VERSION ""

NS_ :

BS_:

BU_: Pegasus Marvel Laptop Stark Xavier stark
VAL_TABLE_ MCU_current_gear 4 "Power" 3 "Eco" 2 "Reverse" 1 "Sports" 0 "Neutral" ;
VAL_TABLE_ Pwm_off_on 1 "On" 0 "Off" ;
VAL_TABLE_ Drive_Mode 1 "Speed" 0 "Torque" ;
VAL_TABLE_ Ready_Status 1 "Ready" 0 "Not Ready" ;
VAL_TABLE_ Fault 1 "Fault" 0 "No fault" ;
VAL_TABLE_ Brake_enable 1 "Drive" 0 "brake" ;
VAL_TABLE_ Motor_direction 1 "Motor fwd" 0 "Motor reverse" ;
VAL_TABLE_ Active_discharge_0n_off 1 "active discharge on" 0 "active discharge off" ;
VAL_TABLE_ Halt_start 1 "Start" 0 "Halt" ;
VAL_TABLE_ Fault_grade 3 "Grade 3 fault" 2 "Grade 2 fault" 1 "Grade 1 fault" 0 "No fault" ;
VAL_TABLE_ MultiMode_Operation 0 "Sports Mode" ;
VAL_TABLE_ Alarm 7 "Speed_limit" 6 "Temp Low" 5 "Under Voltage" 4 "Over Voltage" 3 "Motor Over Heat" 2 "Motor Over Load" 1 "Motor Over Speed" 0 "Encoder_fault" ;
VAL_TABLE_ Vehicle_Status_1 4 "Power on" 3 "Low Voltage Light" 2 "Regnartion_active" 1 "Spr1" 0 "Spr" ;
VAL_TABLE_ Vehicle_status 2 "REV" 1 "FWD" 0 "Park" ;
VAL_TABLE_ MCU_VCU_Fault_Table 1 "fault" 0 "normal" ;
VAL_TABLE_ MCU_VCU_WorkStatus_PWM_Sts 1 "PWM on" 0 "PWM off" ;
VAL_TABLE_ MCU_VCU_WorkStatus_Ctrl_Mode 1 "Speed mode" 0 "Torque mode" ;
VAL_TABLE_ MCU_VCU_WorkStatus_Ready 1 "Ready" 0 "Not Ready" ;
VAL_TABLE_ MCU_VCU_WorkStatus_Fault_Table 1 "fault" 0 "no fault" ;
VAL_TABLE_ MCU_VCU_WorkStatus_Drive_Table 1 "Description for the value '0x1'" 0 "brake" ;
VAL_TABLE_ MCU_VCU_WorkStatus_Direction 1 "motor forward" 0 "motor reverse" ;
VAL_TABLE_ MCU_VCU_WorkStatus_Dischg_Table 1 "active discharge on" 0 "active discharge off" ;
VAL_TABLE_ MCU_VCU_WorkStatus_Halt_Table 1 "start" 0 "halt" ;
VAL_TABLE_ MCU_VCU_Main_Contactor_Table 1 "main contactor on" 0 "main contactor off" ;
VAL_TABLE_ MCU_VCU_Precharge_Table 1 "precharge on" 0 "precharge off" ;
VAL_TABLE_ MCU_VCU_Gear_Table 3 "Brake" 2 "R" 1 "D" 0 "N" ;
VAL_TABLE_ VCU_MCU_HVCircuit_Table 3 "Precharge to main contactor" 2 "main contactor off" 1 "main contactor on" 0 "precharge" ;
VAL_TABLE_ VCU_MCU_Discharge_Table 1 "start" 0 "forbidden" ;
VAL_TABLE_ VCU_MCU_Enable_Table 1 "enable" 0 "disable" ;
VAL_TABLE_ VCU_MCU_Control_Mode_Table 1 "speed" 0 "torque" ;
VAL_TABLE_ VCU_MCU_Valid_Invalid_Table 1 "valid" 0 "invalid" ;

BO_ 3221225472 VECTOR__INDEPENDENT_SIG_MSG: 0 Vector__XXX
 SG_ bms_cycleCount : 0|16@1+ (1,0) [0|65535] "" Vector__XXX
 SG_ bms_mcuCounter : 0|16@1+ (1,0) [0|65535] "" Vector__XXX
 SG_ bms_internalResistance : 0|32@1- (10000,0) [-21474836480000|21474836470000] "" Vector__XXX
 SG_ battery_bms_max_capacity : 0|16@1+ (0.1,0) [0|6553.5] "Ah" Vector__XXX
 SG_ battery_cmu_2_balancing_mask : 0|16@1- (1,0) [0|65535] "" Vector__XXX
 SG_ battery_cmu_1_balancing_mask : 0|16@1- (1,0) [0|65535] "" Vector__XXX
 SG_ battery_bms_errors_since_boot : 0|8@1+ (1,0) [0|255] "" Vector__XXX
 SG_ battery_active_errors_count : 0|16@1+ (1,0) [0|65535] "Value" Vector__XXX
 SG_ battery_state_of_charge : 0|16@1+ (0.01,0) [0|100] "%" Vector__XXX
 SG_ battery_state_of_health : 0|16@1+ (0.01,0) [0|100] "%" Vector__XXX
 SG_ battery_total_voltage : 0|16@1+ (0.1,0) [60|85] "V" Vector__XXX
 SG_ battery_fully_charge_flag : 0|8@1+ (1,0) [0|1] "" Vector__XXX
 SG_ battery_bms_state : 0|8@1+ (1,0) [0|5] "" Vector__XXX
 SG_ battery_precharge_active : 0|8@1+ (1,0) [0|1] "" Vector__XXX
 SG_ battery_balancing_active : 0|8@1+ (1,0) [0|1] "" Vector__XXX
 SG_ battery_current : 0|32@1- (1E-005,0) [-1000|1000] "A" Vector__XXX
 SG_ battery_balancing_limit : 0|16@1+ (0.1,0) [0|4200] "mV" Vector__XXX
 SG_ battery_bms_temperature_1 : 0|8@1+ (1,0) [0|255] "C" Vector__XXX
 SG_ battery_bms_temperature_2 : 0|8@1+ (1,0) [0|255] "C" Vector__XXX
 SG_ battery_bms_temperature_3 : 0|8@1+ (1,0) [0|255] "C" Vector__XXX
 SG_ battery_bms_temperature_4 : 0|8@1+ (1,0) [0|255] "C" Vector__XXX
 SG_ battery_bms_temperature_5 : 0|8@1+ (1,0) [0|255] "C" Vector__XXX
 SG_ battery_bms_temperature_6 : 0|8@1+ (1,0) [0|255] "C" Vector__XXX
 SG_ battery_remaining_battery_capaci : 0|16@1- (0.01,0) [0|3276.7] "Ah" Vector__XXX
 SG_ battery_c_1_v_1 : 0|16@1+ (0.1,0) [3100|4200] "mV" Vector__XXX
 SG_ battery_c_1_v_2 : 0|16@1+ (0.1,0) [3100|4200] "mV" Vector__XXX
 SG_ battery_c_1_v_3 : 0|16@1+ (0.1,0) [3100|4200] "mV" Vector__XXX
 SG_ battery_c_1_v_4 : 0|16@1+ (0.1,0) [3100|4200] "mV" Vector__XXX
 SG_ battery_c_1_v_5 : 0|16@1+ (0.1,0) [3100|4200] "mV" Vector__XXX
 SG_ battery_c_1_v_6 : 0|16@1+ (0.1,0) [3100|4200] "mV" Vector__XXX
 SG_ battery_c_1_v_7 : 0|16@1+ (0.1,0) [3100|4200] "mV" Vector__XXX
 SG_ battery_c_1_v_8 : 0|16@1+ (0.1,0) [3100|4200] "mV" Vector__XXX
 SG_ battery_c_1_v_9 : 0|16@1+ (0.1,0) [3100|4200] "mV" Vector__XXX
 SG_ battery_c_1_v_10 : 0|16@1+ (0.1,0) [3100|4200] "mV" Vector__XXX
 SG_ battery_c_1_v_11 : 0|16@1+ (0.1,0) [3100|4200] "mV" Vector__XXX
 SG_ battery_c_1_v_12 : 0|16@1+ (0.1,0) [3100|4200] "mV" Vector__XXX
 SG_ battery_c_2_v_1 : 0|16@1+ (0.1,0) [3100|4200] "mV" Vector__XXX
 SG_ battery_c_2_v_2 : 0|16@1+ (0.1,0) [3100|4200] "mV" Vector__XXX
 SG_ battery_c_2_v_3 : 0|16@1+ (0.1,0) [3100|4200] "mV" Vector__XXX
 SG_ battery_c_2_v_4 : 0|16@1+ (0.1,0) [3100|4200] "mV" Vector__XXX
 SG_ battery_c_2_v_9 : 0|16@1+ (0.1,0) [3100|4200] "mV" Vector__XXX
 SG_ battery_c_2_v_10 : 0|16@1+ (0.1,0) [3100|4200] "mV" Vector__XXX
 SG_ battery_c_2_v_11 : 0|16@1+ (0.1,0) [3100|4200] "mV" Vector__XXX
 SG_ battery_c_2_v_12 : 0|16@1+ (0.1,0) [3100|4200] "mV" Vector__XXX
 SG_ battery_c_2_v_5 : 0|16@1+ (0.1,0) [3100|4200] "mV" Vector__XXX
 SG_ battery_c_2_v_6 : 0|16@1+ (0.1,0) [3100|4200] "mV" Vector__XXX
 SG_ battery_c_2_v_7 : 0|16@1+ (0.1,0) [3100|4200] "mV" Vector__XXX
 SG_ battery_c_2_v_8 : 0|16@1+ (0.1,0) [3100|4200] "mV" Vector__XXX
 SG_ battery_bms_dynamic_in_limit : 0|16@1- (0.1,0) [-3276.8|3276.7] "A" Vector__XXX
 SG_ battery_bms_dynamic_out_limit : 0|16@1- (0.1,0) [-3276.8|3276.7] "A" Vector__XXX
 SG_ battery_bms_config_id : 0|8@1- (1,0) [-128|127] "" Vector__XXX
 SG_ battery_bms_version : 0|16@1+ (1,0) [0|4294967295] "" Vector__XXX
 SG_ battery_bms_requested_current : 0|16@0+ (0.1,0) [0|6553.5] "" Vector__XXX
 SG_ battery_bms_requested_voltage : 0|16@0+ (0.1,0) [0|6553.5] "" Vector__XXX
 SG_ controller_os_version : 0|8@1+ (1,0) [0|255] "" Vector__XXX
 SG_ controller_vcl_build_number : 0|8@1+ (1,0) [0|255] "" Vector__XXX
 SG_ controller_vcl_version : 0|8@1+ (1,0) [0|255] "" Vector__XXX
 SG_ controller_serial_number : 0|24@1+ (1,0) [0|255] "" Vector__XXX
 SG_ controller_config_version : 0|8@1+ (1,0) [0|0] "" Vector__XXX
 SG_ controller_os_build_number : 0|8@1+ (1,0) [0|0] "" Vector__XXX
 SG_ Baud_Rate_Change : 0|8@1+ (1,0) [0|2] "" Vector__XXX
 SG_ Regen_Off : 0|8@1+ (1,0) [0|255] "" Vector__XXX
 SG_ Brake_Current_Limit : 0|8@1+ (1,0) [5|100] "Percent" Vector__XXX
 SG_ Regen_Current_Limit : 0|8@1+ (1,0) [5|100] "Percent" Vector__XXX
 SG_ Drive_Current_Limit : 0|8@1+ (1,0) [10|100] "Percent" Vector__XXX
 SG_ Brake_Rate : 0|8@1+ (0.1,0) [1|250] "Sec" Vector__XXX
 SG_ Accel_Release_Rate : 0|8@1- (0.1,0) [1|250] "Sec" Vector__XXX
 SG_ Accel_Rate : 0|8@1+ (0.1,0) [1|250] "Sec" Vector__XXX
 SG_ Invalid_BMS_Data : 0|8@1+ (1,0) [0|255] "" Vector__XXX
 SG_ controller_vehicle_power_mode : 0|8@1+ (1,0) [0|255] "" Vector__XXX
 SG_ controller_battery_energy_consum : 0|8@1+ (0.1,0) [0|25.5] "KWhr" Vector__XXX
 SG_ controller_battery_power_consume : 0|8@1+ (0.1,0) [0|25.5] "KW" Vector__XXX
 SG_ controller_motor_torque_estimate : 0|16@1- (0.1,0) [-100|100] "Nm" Vector__XXX
 SG_ controller_main_state : 0|8@1+ (1,0) [0|0] "" Vector__XXX
 SG_ controller_frequency : 0|16@1- (1,0) [-500|500] "Hz" Vector__XXX
 SG_ controller_current_rms : 0|16@1+ (1,0) [0|255] "%" Vector__XXX
 SG_ controller_voltage_rms : 0|8@1+ (1,0) [0|255] "Amp" Vector__XXX
 SG_ controller_master_timer : 0|32@1- (1,0) [-2147483648|2147483647] "" Vector__XXX
 SG_ controller_motor_rpm : 0|16@1+ (1,0) [0|65535] "RPM" Vector__XXX
 SG_ controller_battery_keyswitch_vol : 0|8@1+ (1,0) [0|255] "Volt" Vector__XXX
 SG_ controller_battery_capacity_volt : 0|8@1+ (1,0) [0|255] "Volt" Vector__XXX
 SG_ controller_potential_to_row : 0|8@1+ (0.1,0) [0|25.5] "V" Vector__XXX
 SG_ controller_brake_mapped : 0|8@1+ (1,0) [0|255] "%" Vector__XXX
 SG_ controller_brake_command : 0|8@1+ (1,0) [0|255] "%" Vector__XXX
 SG_ controller_throttle_potentiomete : 0|8@1+ (0.1,0) [0|25.5] "V" Vector__XXX
 SG_ controller_throttle_mapped : 0|8@1+ (1,0) [0|255] "%" Vector__XXX
 SG_ controller_throttle_multiplier : 0|8@1+ (1,0) [0|255] "%" Vector__XXX
 SG_ controller_throttle_command : 0|8@1+ (1,0) [0|255] "%" Vector__XXX
 SG_ controller_fault_flag_0 : 0|8@1+ (1,0) [0|255] "" Vector__XXX
 SG_ controller_fault_flag_1 : 0|8@1+ (1,0) [0|255] "" Vector__XXX
 SG_ controller_fault_flag_2 : 0|8@1+ (1,0) [0|255] "" Vector__XXX
 SG_ controller_fault_flag_3 : 0|8@1+ (1,0) [0|255] "" Vector__XXX
 SG_ controller_fault_flag_4 : 0|8@1+ (1,0) [0|255] "" Vector__XXX
 SG_ controller_fault_flag_5 : 0|8@1+ (1,0) [0|255] "" Vector__XXX
 SG_ controller_fault_flag_6 : 0|8@1+ (1,0) [0|255] "" Vector__XXX
 SG_ controller_fault_flag_7 : 0|8@1+ (1,0) [0|255] "" Vector__XXX
 SG_ controller_trip_low_high : 0|16@1+ (1,0) [0|255] "%" Vector__XXX
 SG_ controller_alarm_fault : 0|8@1+ (1,0) [0|255] "" Vector__XXX
 SG_ controller_assist_level_gear : 0|8@1+ (1,0) [0|255] "" Vector__XXX
 SG_ controller_vehicle_status : 0|8@1+ (1,0) [0|0] "" Vector__XXX
 SG_ controller_odometer : 0|32@1+ (0.1,0) [0|429496729.5] "KM" Vector__XXX
 SG_ controller_battery_discharge_rat : 0|8@1- (1,0) [-128|127] "" Vector__XXX
 SG_ controller_soc : 0|8@1- (1,0) [-128|127] "" Vector__XXX
 SG_ controller_temperature : 0|8@1+ (1,-50) [-50|200] "degree_C" Vector__XXX
 SG_ controller_motor_temperature : 0|8@1+ (1,-50) [-50|200] "Degree_C" Vector__XXX
 SG_ VCU_Canlife : 0|4@1+ (1,0) [0|0] "" Vector__XXX
 SG_ VCU_HVCircuit : 0|2@1+ (1,0) [0|0] "" Vector__XXX
 SG_ VCU_Discharge : 0|1@1+ (1,0) [0|0] "" Vector__XXX
 SG_ VCU_Enable : 0|1@1+ (1,0) [0|0] "" Vector__XXX
 SG_ VCU_ModeReq_control_mode : 0|1@1+ (1,0) [0|0] "" Vector__XXX
 SG_ VCU_ModeReq_reverse : 0|1@1+ (1,0) [0|0] "" Vector__XXX
 SG_ VCU_ModeReq_brake : 0|1@1+ (1,0) [0|0] "" Vector__XXX
 SG_ VCU_ModeReq_forward : 0|1@1+ (1,0) [0|0] "" Vector__XXX
 SG_ VCU_ModeReq_idle : 0|1@1+ (1,0) [0|0] "" Vector__XXX
 SG_ VCU_ModeReq_halt : 0|1@1+ (1,0) [0|0] "" Vector__XXX
 SG_ VCU_SpdReq : 0|16@1+ (1,-32000) [0|0] "rpm" Vector__XXX
 SG_ VCU_TrqReq : 0|16@1+ (0.1,-3200) [0|0] "Nm" Vector__XXX

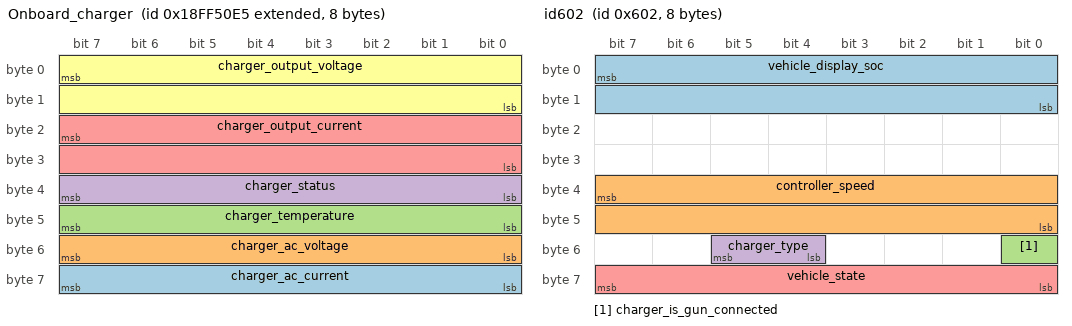
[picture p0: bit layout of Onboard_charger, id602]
BO_ 2566869221 Onboard_charger: 8 Vector__XXX
 SG_ charger_ac_current : 63|8@0+ (0.1,0) [0|255] "" Vector__XXX
 SG_ charger_ac_voltage : 55|8@0+ (1,0) [0|255] "" Vector__XXX
 SG_ charger_temperature : 47|8@0+ (1,0) [0|255] "" Vector__XXX
 SG_ charger_status : 39|8@0+ (1,0) [0|255] "" Vector__XXX
 SG_ charger_output_current : 23|16@0+ (0.1,0) [0|255] "" Vector__XXX
 SG_ charger_output_voltage : 7|16@0+ (0.1,0) [0|255] "" Vector__XXX

BO_ 2550588916 Stark_charger: 8 Vector__XXX
 SG_ charger_requested_current : 23|16@0+ (0.1,0) [0|255] "" Vector__XXX
 SG_ charger_requested_voltage : 7|16@0+ (0.1,0) [0|255] "" Vector__XXX

BO_ 1538 id602: 8 stark
 SG_ vehicle_display_soc : 7|16@0+ (0.1,0) [0|0] "" Vector__XXX
 SG_ controller_speed : 39|16@0+ (0.1,0) [0|65535] "" Vector__XXX
 SG_ charger_is_gun_connected : 48|1@1+ (1,0) [0|2] "" Vector__XXX
 SG_ charger_type : 52|2@1+ (1,0) [0|3] "" Vector__XXX
 SG_ vehicle_state : 63|8@0+ (1,0) [0|10] "" Vector__XXX

BO_ 1539 id603: 8 stark
 SG_ vehicle_calculated_odo : 23|32@0+ (0.01,0) [0|429496729.5] "Km" Vector__XXX

BO_ 1542 id606: 8 Vector__XXX
 SG_ vehicle_aux_charing_flag : 7|8@0+ (1,0) [0|3] "" Vector__XXX
 SG_ vehicle_aux_battery_voltage : 15|16@0+ (0.01,0) [0|655.35] "" Vector__XXX

BO_ 1541 id605: 8 Vector__XXX
 SG_ vehicle_stark_ticks : 7|32@0+ (1,0) [0|4294967295] "" Vector__XXX
 SG_ telemetry_start_index : 39|32@0+ (1,0) [0|4294967295] "" Vector__XXX

BO_ 1545 id609: 8 Vector__XXX
 SG_ vehicle_igni_debounce_count : 39|32@0+ (1,0) [0|4294967295] "" Vector__XXX
 SG_ vehicle_igni_cycle_count : 7|32@0+ (1,0) [0|4294967295] "" Vector__XXX

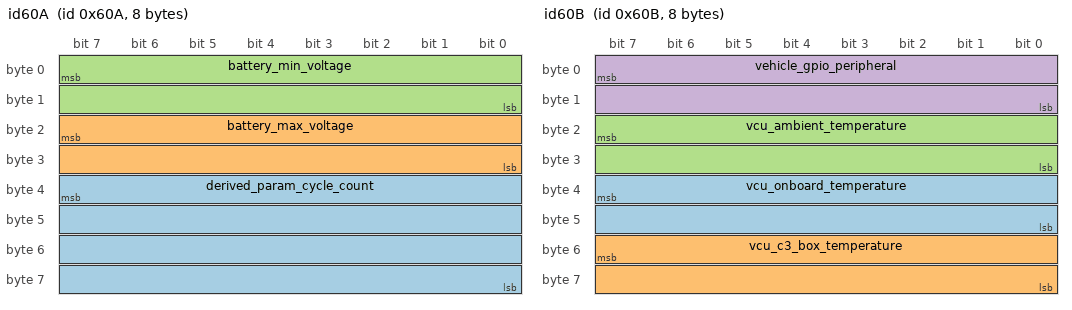
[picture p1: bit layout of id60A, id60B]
BO_ 1546 id60A: 8 Vector__XXX
 SG_ derived_param_cycle_count : 39|32@0+ (1,0) [0|4294967295] "" Vector__XXX
 SG_ battery_max_voltage : 23|16@0+ (0.1,0) [0|6553.5] "" Vector__XXX
 SG_ battery_min_voltage : 7|16@0+ (0.1,0) [0|6553.5] "" Vector__XXX

BO_ 1547 id60B: 8 Vector__XXX
 SG_ vcu_onboard_temperature : 39|16@0+ (0.1,0) [0|6553.5] "C" Vector__XXX
 SG_ vcu_c3_box_temperature : 55|16@0+ (0.1,0) [0|6553.5] "C" Vector__XXX
 SG_ vcu_ambient_temperature : 23|16@0+ (0.1,0) [0|6553.5] "C" Vector__XXX
 SG_ vehicle_gpio_peripheral : 7|16@0+ (1,0) [0|65535] "" Vector__XXX

BO_ 1548 id60C: 8 Vector__XXX
 SG_ vcu_uid1 : 7|64@0+ (1,0) [0|1.8446744074E+019] "" Vector__XXX

BO_ 1549 id60D: 8 Vector__XXX
 SG_ vcu_uid2 : 7|32@0+ (1,0) [0|4294967295] "" Vector__XXX

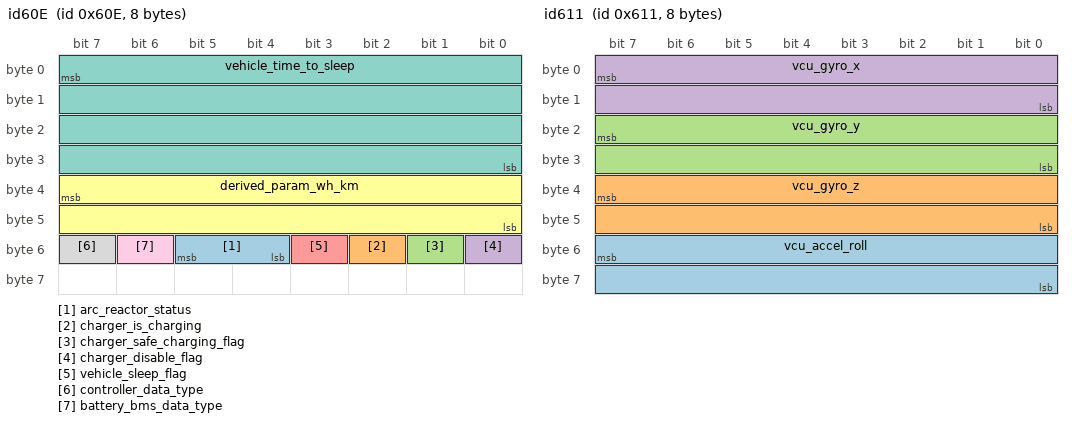
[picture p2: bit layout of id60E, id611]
BO_ 1550 id60E: 8 Vector__XXX
 SG_ arc_reactor_status : 52|2@1+ (1,0) [0|3] "" Vector__XXX
 SG_ charger_is_charging : 50|1@1+ (1,0) [0|1] "" Vector__XXX
 SG_ charger_safe_charging_flag : 49|1@1+ (1,0) [0|1] "" Vector__XXX
 SG_ charger_disable_flag : 48|1@1+ (1,0) [0|1] "" Vector__XXX
 SG_ vehicle_sleep_flag : 51|1@1+ (1,0) [0|1] "" Vector__XXX
 SG_ derived_param_wh_km : 39|16@0+ (0.1,0) [0|6553.5] "" Vector__XXX
 SG_ vehicle_time_to_sleep : 7|32@0+ (1,0) [0|4294967295] "" Vector__XXX
 SG_ controller_data_type : 55|1@1+ (1,0) [0|0] "" Vector__XXX
 SG_ battery_bms_data_type : 54|1@1+ (1,0) [0|0] "" Vector__XXX

BO_ 1552 id610: 8 Vector__XXX
 SG_ vehicle_ecu_manifest_crc : 39|32@0+ (1,0) [0|4294967295] "" Vector__XXX
 SG_ vehicle_manifest_crc : 7|32@0+ (1,0) [0|4294967295] "" Vector__XXX

BO_ 1553 id611: 8 Vector__XXX
 SG_ vcu_accel_roll : 55|16@0- (0.01,0) [-32768|32767] "" Vector__XXX
 SG_ vcu_gyro_z : 39|16@0- (0.01,0) [-32768|32767] "" Vector__XXX
 SG_ vcu_gyro_y : 23|16@0- (0.01,0) [-32768|32767] "" Vector__XXX
 SG_ vcu_gyro_x : 7|16@0- (0.01,0) [-327.68|327.67] "" Vector__XXX

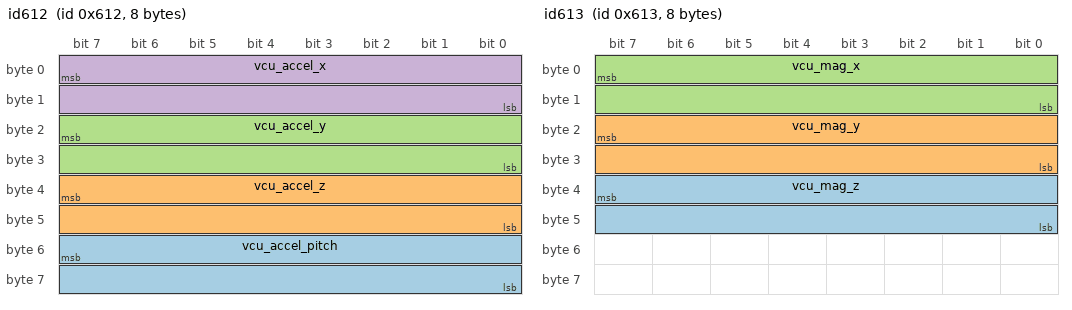
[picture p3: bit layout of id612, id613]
BO_ 1554 id612: 8 Vector__XXX
 SG_ vcu_accel_pitch : 55|16@0- (0.01,0) [-32768|32767] "" Vector__XXX
 SG_ vcu_accel_z : 39|16@0- (0.01,0) [-32768|32767] "" Vector__XXX
 SG_ vcu_accel_y : 23|16@0- (0.01,0) [-32768|32767] "" Vector__XXX
 SG_ vcu_accel_x : 7|16@0- (0.01,0) [-327.68|327.67] "" Vector__XXX

BO_ 1555 id613: 8 Vector__XXX
 SG_ vcu_mag_z : 39|16@0- (0.1,0) [-32768|32767] "" Vector__XXX
 SG_ vcu_mag_y : 23|16@0- (0.1,0) [-32768|32767] "" Vector__XXX
 SG_ vcu_mag_x : 7|16@0- (0.1,0) [-327.68|327.67] "" Vector__XXX

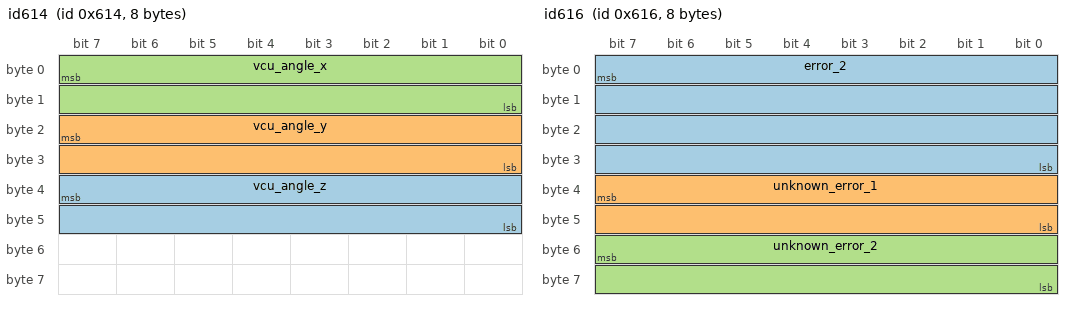
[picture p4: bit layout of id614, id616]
BO_ 1556 id614: 8 Vector__XXX
 SG_ vcu_angle_z : 39|16@0- (0.1,0) [-32768|32767] "" Vector__XXX
 SG_ vcu_angle_y : 23|16@0- (0.1,0) [-32768|32767] "" Vector__XXX
 SG_ vcu_angle_x : 7|16@0- (0.1,0) [-327.68|327.67] "" Vector__XXX

BO_ 1557 id615: 8 Vector__XXX
 SG_ error_1 : 7|64@0+ (1,0) [-32768|32767] "" Vector__XXX

BO_ 1558 id616: 8 Vector__XXX
 SG_ error_2 : 7|32@0+ (1,0) [-32768|32767] "" Vector__XXX
 SG_ unknown_error_1 : 39|16@0+ (1,0) [-32768|32767] "" Vector__XXX
 SG_ unknown_error_2 : 55|16@0+ (1,0) [-327.68|327.67] "" Vector__XXX

BO_ 1559 id617: 8 Vector__XXX
 SG_ controller_error : 7|32@0+ (1,0) [0|0] "" Vector__XXX

BO_ 1026 display_3: 8 Stark
 SG_ vehicle_calculated_trip : 32|32@1+ (0.1,0) [0|0] ""  Xavier

BO_ 1025 display_2: 8 Stark
 SG_ vehicle_ttfc : 32|16@1+ (1,0) [0|0] ""  Xavier
 SG_ vehicle_range : 16|16@1+ (0.1,0) [0|0] ""  Xavier

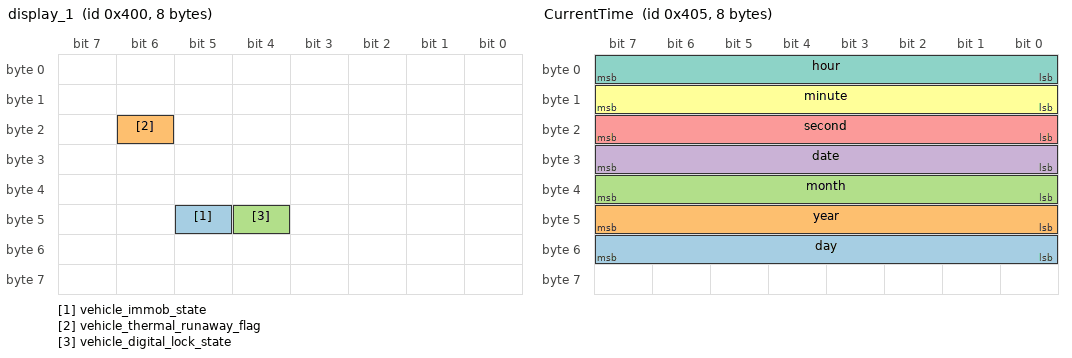
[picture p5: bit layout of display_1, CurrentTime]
BO_ 1024 display_1: 8 Stark
 SG_ vehicle_immob_state : 45|1@1+ (1,0) [0|1] "" Vector__XXX
 SG_ vehicle_thermal_runaway_flag : 22|1@1+ (1,0) [0|1] "" Vector__XXX
 SG_ vehicle_digital_lock_state : 44|1@1+ (1,0) [0|1] "" Vector__XXX

BO_ 1969 GetGITSHA: 8 Xavier
 SG_ git_shaw : 16|32@1+ (1,0) [0|4294967295] ""  Laptop
 SG_ device_id : 0|8@1+ (1,0) [0|255] ""  Laptop

BO_ 1029 CurrentTime: 8 Xavier
 SG_ day : 48|8@1+ (1,0) [0|255] ""  Laptop,Stark
 SG_ year : 40|8@1+ (1,0) [0|255] ""  Laptop,Stark
 SG_ month : 32|8@1+ (1,0) [0|255] ""  Laptop,Stark
 SG_ date : 24|8@1+ (1,0) [0|255] ""  Laptop,Stark
 SG_ second : 16|8@1+ (1,0) [0|255] ""  Laptop,Stark
 SG_ minute : 8|8@1+ (1,0) [0|255] ""  Laptop,Stark
 SG_ hour : 0|8@1+ (1,0) [0|255] ""  Laptop,Stark

BO_ 1783 sim_number_16_20: 8 Xavier
 SG_ sim_16_20 : 0|32@1+ (1,0) [0|4294967295] ""  Laptop

BO_ 1782 sim_number_0_16: 8 Xavier
 SG_ sim_0_16 : 0|64@1+ (1,0) [0|9.2233720369E+018] ""  Laptop

BO_ 1779 xavier_1: 8 Xavier
 SG_ imei : 0|64@1+ (1,0) [0|9.2233720369E+018] ""  Laptop

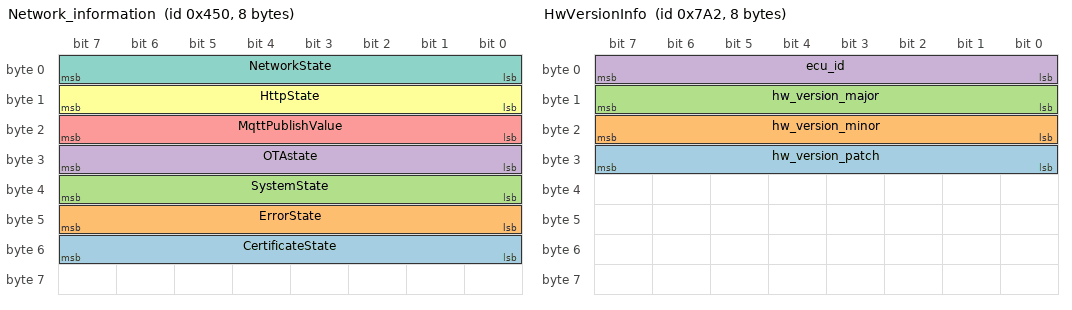
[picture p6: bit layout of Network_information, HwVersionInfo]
BO_ 1104 Network_information: 8 Xavier
 SG_ CertificateState : 48|8@1+ (1,0) [0|255] ""  Laptop
 SG_ ErrorState : 40|8@1+ (1,0) [0|255] ""  Laptop
 SG_ SystemState : 32|8@1+ (1,0) [0|255] ""  Laptop
 SG_ OTAstate : 24|8@1+ (1,0) [0|255] ""  Laptop
 SG_ MqttPublishValue : 16|8@1+ (1,0) [0|255] ""  Laptop
 SG_ HttpState : 8|8@1+ (1,0) [0|255] ""  Laptop
 SG_ NetworkState : 0|8@1+ (1,0) [0|0] ""  Laptop

BO_ 1954 HwVersionInfo: 8 Xavier
 SG_ hw_version_patch : 24|8@1+ (1,0) [0|255] ""  Laptop,Stark
 SG_ hw_version_minor : 16|8@1+ (1,0) [0|255] ""  Laptop,Stark
 SG_ hw_version_major : 8|8@1+ (1,0) [0|255] ""  Laptop,Stark
 SG_ ecu_id : 0|8@1+ (1,0) [0|255] ""  Stark,Laptop

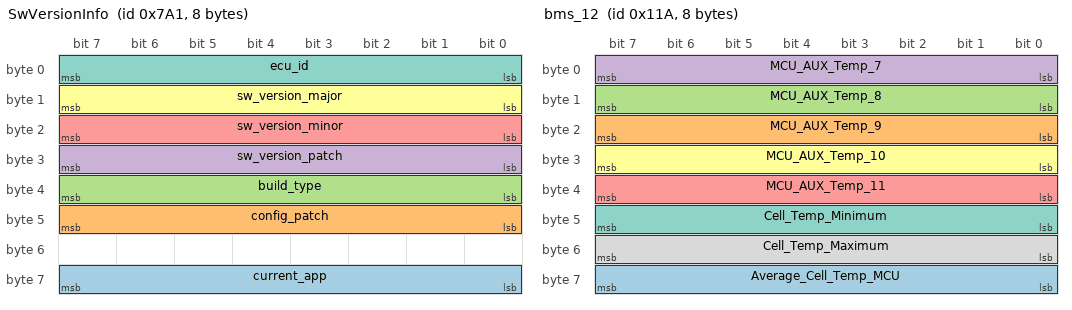
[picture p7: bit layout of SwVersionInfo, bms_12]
BO_ 1953 SwVersionInfo: 8 Xavier
 SG_ current_app : 56|8@1+ (1,0) [0|255] ""  Laptop,Stark
 SG_ config_patch : 40|8@1+ (1,0) [0|255] ""  Laptop,Stark
 SG_ build_type : 32|8@1+ (1,0) [0|255] ""  Laptop,Stark
 SG_ sw_version_patch : 24|8@1+ (1,0) [0|255] ""  Laptop,Stark
 SG_ sw_version_minor : 16|8@1+ (1,0) [0|255] ""  Laptop,Stark
 SG_ sw_version_major : 8|8@1+ (1,0) [0|255] ""  Laptop,Stark
 SG_ ecu_id : 0|8@1+ (1,0) [0|255] ""  Laptop,Stark

BO_ 282 bms_12: 8 Vector__XXX
 SG_ Average_Cell_Temp_MCU : 56|8@1+ (1,0) [0|255] "C" Vector__XXX
 SG_ MCU_AUX_Temp_9 : 16|8@1+ (1,0) [0|255] "C" Vector__XXX
 SG_ MCU_AUX_Temp_8 : 8|8@1+ (1,0) [0|255] "C" Vector__XXX
 SG_ MCU_AUX_Temp_7 : 0|8@1+ (1,0) [0|255] "C" Vector__XXX
 SG_ MCU_AUX_Temp_11 : 32|8@1+ (1,0) [0|255] "C" Vector__XXX
 SG_ MCU_AUX_Temp_10 : 24|8@1+ (1,0) [0|255] "C" Vector__XXX
 SG_ Cell_Temp_Minimum : 40|8@1+ (1,0) [0|255] "C" Vector__XXX
 SG_ Cell_Temp_Maximum : 48|8@1+ (1,0) [0|255] "C" Vector__XXX

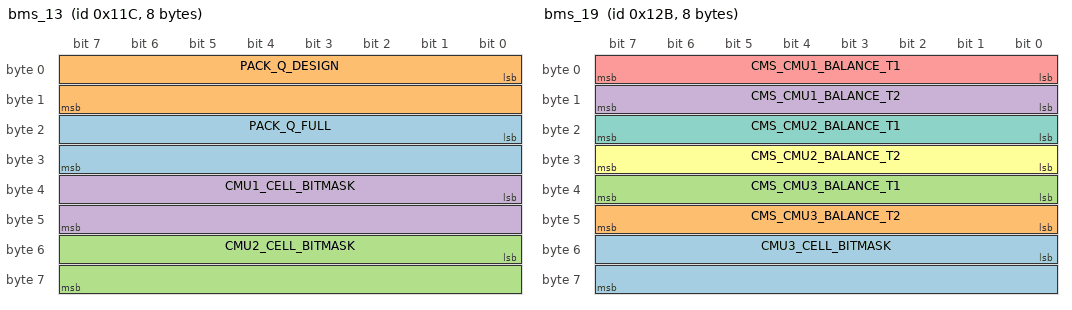
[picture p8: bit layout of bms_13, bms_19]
BO_ 284 bms_13: 8 Vector__XXX
 SG_ PACK_Q_FULL : 16|16@1+ (0.1,0) [0|6553.5] "Ah" Vector__XXX
 SG_ PACK_Q_DESIGN : 0|16@1+ (0.1,0) [0|6553.5] "Ah" Vector__XXX
 SG_ CMU2_CELL_BITMASK : 48|16@1+ (1,0) [0|65535] "" Vector__XXX
 SG_ CMU1_CELL_BITMASK : 32|16@1+ (1,0) [0|65535] "" Vector__XXX

BO_ 299 bms_19: 8 Vector__XXX
 SG_ CMU3_CELL_BITMASK : 48|16@1+ (1,0) [0|65535] "" Vector__XXX
 SG_ CMS_CMU3_BALANCE_T2 : 40|8@1+ (1,0) [0|255] "C" Vector__XXX
 SG_ CMS_CMU3_BALANCE_T1 : 32|8@1+ (1,0) [0|255] "C" Vector__XXX
 SG_ CMS_CMU1_BALANCE_T2 : 8|8@1+ (1,0) [0|255] "C" Vector__XXX
 SG_ CMS_CMU1_BALANCE_T1 : 0|8@1+ (1,0) [0|255] "C" Vector__XXX
 SG_ CMS_CMU2_BALANCE_T2 : 24|8@1+ (1,0) [0|255] "C" Vector__XXX
 SG_ CMS_CMU2_BALANCE_T1 : 16|8@1+ (1,0) [0|255] "C" Vector__XXX

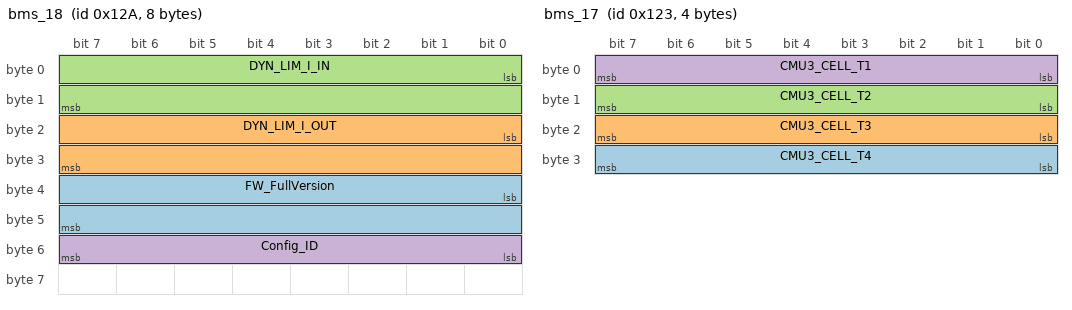
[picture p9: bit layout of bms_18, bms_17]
BO_ 298 bms_18: 8 Vector__XXX
 SG_ FW_FullVersion : 32|16@1+ (1,0) [0|65535] "" Vector__XXX
 SG_ DYN_LIM_I_OUT : 16|16@1+ (0.1,0) [0|6553.5] "A" Vector__XXX
 SG_ DYN_LIM_I_IN : 0|16@1+ (0.1,0) [0|6553.5] "A" Vector__XXX
 SG_ Config_ID : 48|8@1+ (1,0) [0|255] "" Vector__XXX

BO_ 291 bms_17: 4 Vector__XXX
 SG_ CMU3_CELL_T4 : 24|8@1+ (1,0) [0|255] "C" Vector__XXX
 SG_ CMU3_CELL_T3 : 16|8@1+ (1,0) [0|255] "C" Vector__XXX
 SG_ CMU3_CELL_T2 : 8|8@1+ (1,0) [0|255] "C" Vector__XXX
 SG_ CMU3_CELL_T1 : 0|8@1+ (1,0) [0|255] "C" Vector__XXX

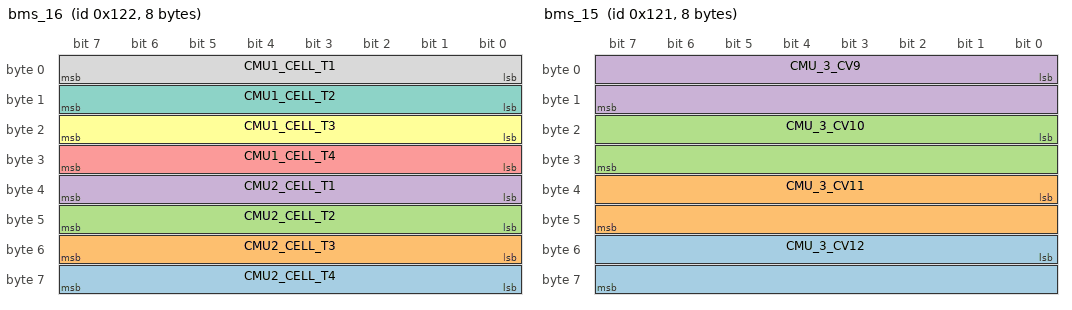
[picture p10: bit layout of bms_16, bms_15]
BO_ 290 bms_16: 8 Vector__XXX
 SG_ CMU2_CELL_T4 : 56|8@1+ (1,0) [0|255] "C" Vector__XXX
 SG_ CMU2_CELL_T3 : 48|8@1+ (1,0) [0|255] "C" Vector__XXX
 SG_ CMU2_CELL_T2 : 40|8@1+ (1,0) [0|255] "C" Vector__XXX
 SG_ CMU2_CELL_T1 : 32|8@1+ (1,0) [0|255] "C" Vector__XXX
 SG_ CMU1_CELL_T4 : 24|8@1+ (1,0) [0|255] "C" Vector__XXX
 SG_ CMU1_CELL_T3 : 16|8@1+ (1,0) [0|255] "C" Vector__XXX
 SG_ CMU1_CELL_T2 : 8|8@1+ (1,0) [0|255] "C" Vector__XXX
 SG_ CMU1_CELL_T1 : 0|8@1+ (1,0) [0|255] "C" Vector__XXX

BO_ 289 bms_15: 8 Vector__XXX
 SG_ CMU_3_CV12 : 48|16@1+ (0.1,0) [0|6553.5] "mV" Vector__XXX
 SG_ CMU_3_CV11 : 32|16@1+ (0.1,0) [0|6553.5] "mV" Vector__XXX
 SG_ CMU_3_CV10 : 16|16@1+ (0.1,0) [0|6553.5] "mV" Vector__XXX
 SG_ CMU_3_CV9 : 0|16@1+ (0.1,0) [0|6553.5] "mV" Vector__XXX

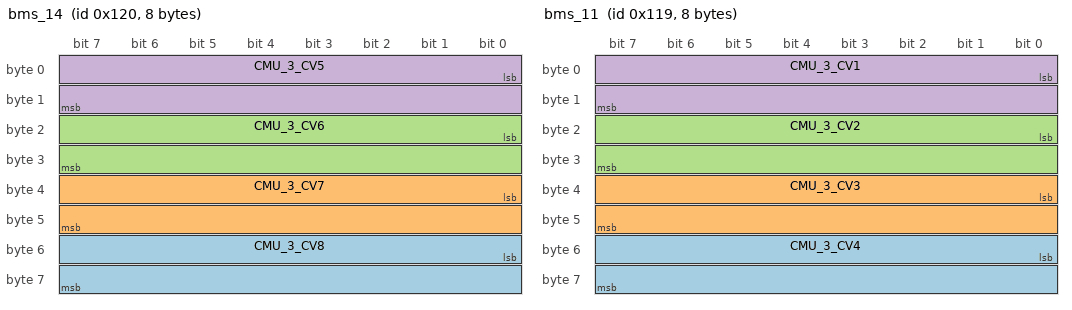
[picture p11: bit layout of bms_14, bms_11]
BO_ 288 bms_14: 8 Vector__XXX
 SG_ CMU_3_CV8 : 48|16@1+ (0.1,0) [0|6553.5] "mV" Vector__XXX
 SG_ CMU_3_CV7 : 32|16@1+ (0.1,0) [0|6553.5] "mV" Vector__XXX
 SG_ CMU_3_CV6 : 16|16@1+ (0.1,0) [0|6553.5] "mV" Vector__XXX
 SG_ CMU_3_CV5 : 0|16@1+ (0.1,0) [0|6553.5] "mV" Vector__XXX

BO_ 281 bms_11: 8 Vector__XXX
 SG_ CMU_3_CV4 : 48|16@1+ (0.1,0) [0|6553.5] "mV" Vector__XXX
 SG_ CMU_3_CV3 : 32|16@1+ (0.1,0) [0|6553.5] "mV" Vector__XXX
 SG_ CMU_3_CV2 : 16|16@1+ (0.1,0) [0|6553.5] "mV" Vector__XXX
 SG_ CMU_3_CV1 : 0|16@1+ (0.1,0) [0|6553.5] "mV" Vector__XXX

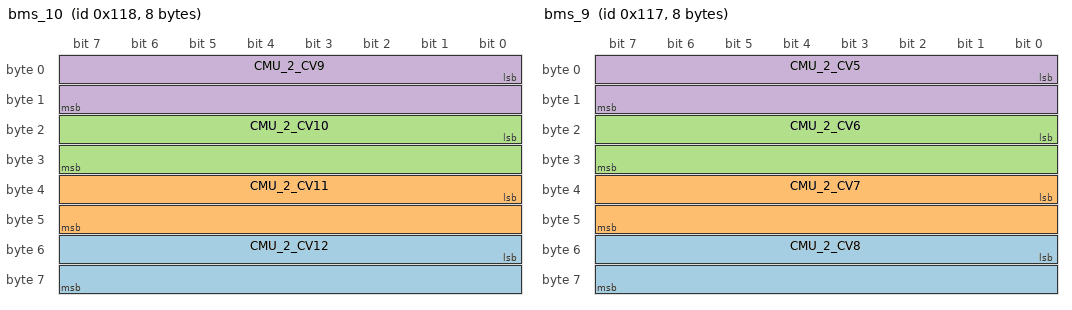
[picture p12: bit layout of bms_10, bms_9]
BO_ 280 bms_10: 8 Vector__XXX
 SG_ CMU_2_CV12 : 48|16@1+ (0.1,0) [0|6553.5] "mV" Vector__XXX
 SG_ CMU_2_CV11 : 32|16@1+ (0.1,0) [0|6553.5] "mV" Vector__XXX
 SG_ CMU_2_CV10 : 16|16@1+ (0.1,0) [0|6553.5] "mV" Vector__XXX
 SG_ CMU_2_CV9 : 0|16@1+ (0.1,0) [0|6553.5] "mV" Vector__XXX

BO_ 279 bms_9: 8 Vector__XXX
 SG_ CMU_2_CV8 : 48|16@1+ (0.1,0) [0|6553.5] "mV" Vector__XXX
 SG_ CMU_2_CV7 : 32|16@1+ (0.1,0) [0|6553.5] "mV" Vector__XXX
 SG_ CMU_2_CV6 : 16|16@1+ (0.1,0) [0|6553.5] "mV" Vector__XXX
 SG_ CMU_2_CV5 : 0|16@1+ (0.1,0) [0|6553.5] "mV" Vector__XXX

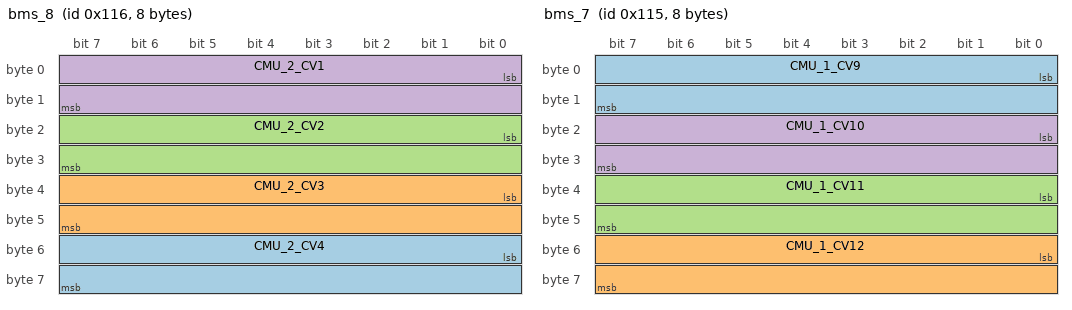
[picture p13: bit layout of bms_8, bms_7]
BO_ 278 bms_8: 8 Vector__XXX
 SG_ CMU_2_CV4 : 48|16@1+ (0.1,0) [0|6553.5] "mV" Vector__XXX
 SG_ CMU_2_CV3 : 32|16@1+ (0.1,0) [0|6553.5] "mV" Vector__XXX
 SG_ CMU_2_CV2 : 16|16@1+ (0.1,0) [0|6553.5] "mV" Vector__XXX
 SG_ CMU_2_CV1 : 0|16@1+ (0.1,0) [0|6553.5] "mV" Vector__XXX

BO_ 277 bms_7: 8 Vector__XXX
 SG_ CMU_1_CV9 : 0|16@1+ (0.1,0) [0|6553.5] "mV" Vector__XXX
 SG_ CMU_1_CV12 : 48|16@1+ (0.1,0) [0|6553.5] "mV" Vector__XXX
 SG_ CMU_1_CV11 : 32|16@1+ (0.1,0) [0|6553.5] "mV" Vector__XXX
 SG_ CMU_1_CV10 : 16|16@1+ (0.1,0) [0|6553.5] "mV" Vector__XXX

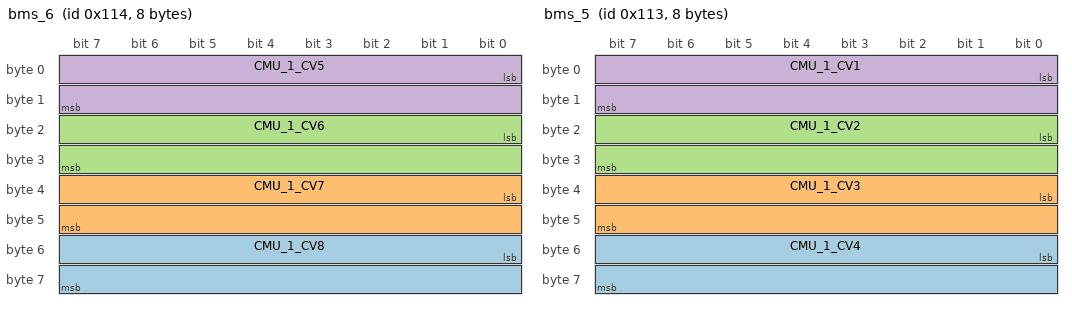
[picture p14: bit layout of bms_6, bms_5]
BO_ 276 bms_6: 8 Vector__XXX
 SG_ CMU_1_CV8 : 48|16@1+ (0.1,0) [0|6553.5] "mV" Vector__XXX
 SG_ CMU_1_CV7 : 32|16@1+ (0.1,0) [0|6553.5] "mV" Vector__XXX
 SG_ CMU_1_CV6 : 16|16@1+ (0.1,0) [0|6553.5] "mV" Vector__XXX
 SG_ CMU_1_CV5 : 0|16@1+ (0.1,0) [0|6553.5] "mV" Vector__XXX

BO_ 275 bms_5: 8 Vector__XXX
 SG_ CMU_1_CV4 : 48|16@1+ (0.1,0) [0|6553.5] "mV" Vector__XXX
 SG_ CMU_1_CV3 : 32|16@1+ (0.1,0) [0|6553.5] "mV" Vector__XXX
 SG_ CMU_1_CV2 : 16|16@1+ (0.1,0) [0|6553.5] "mV" Vector__XXX
 SG_ CMU_1_CV1 : 0|16@1+ (0.1,0) [0|6553.5] "mV" Vector__XXX

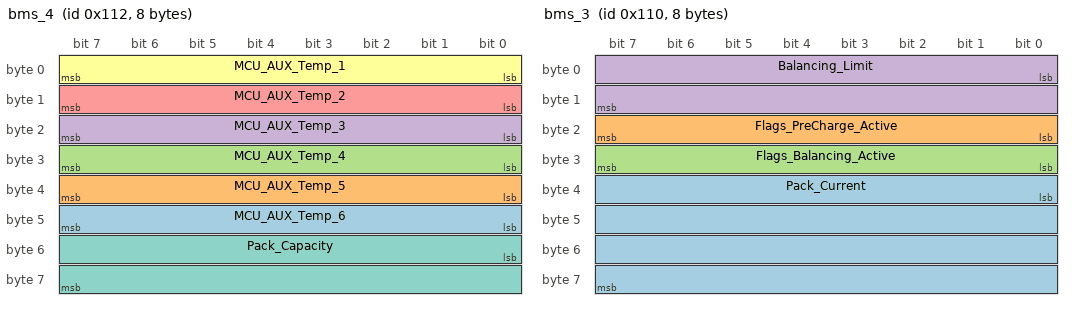
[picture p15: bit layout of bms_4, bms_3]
BO_ 274 bms_4: 8 Vector__XXX
 SG_ MCU_AUX_Temp_6 : 40|8@1+ (1,0) [0|255] "C" Vector__XXX
 SG_ MCU_AUX_Temp_5 : 32|8@1+ (1,0) [0|255] "C" Vector__XXX
 SG_ MCU_AUX_Temp_4 : 24|8@1+ (1,0) [0|255] "C" Vector__XXX
 SG_ MCU_AUX_Temp_3 : 16|8@1+ (1,0) [0|255] "C" Vector__XXX
 SG_ MCU_AUX_Temp_2 : 8|8@1+ (1,0) [0|255] "C" Vector__XXX
 SG_ MCU_AUX_Temp_1 : 0|8@1+ (1,0) [0|255] "C" Vector__XXX
 SG_ Pack_Capacity : 48|16@1+ (0.1,0) [0|6553.5] "Ah" Vector__XXX

BO_ 272 bms_3: 8 Vector__XXX
 SG_ Pack_Current : 32|32@1- (1E-005,0) [-21474836.48|21474836.47] "A" Vector__XXX
 SG_ Flags_PreCharge_Active : 16|8@1+ (1,0) [0|255] "" Vector__XXX
 SG_ Flags_Balancing_Active : 24|8@1+ (1,0) [0|255] "" Vector__XXX
 SG_ Balancing_Limit : 0|16@1+ (0.1,0) [0|65535] "mV" Vector__XXX

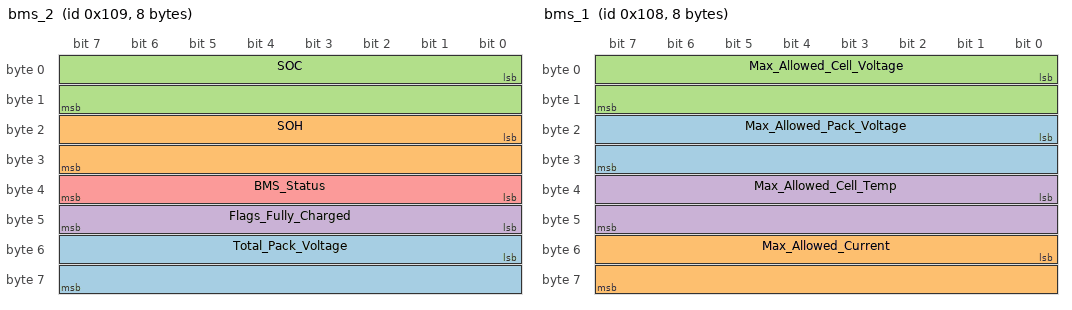
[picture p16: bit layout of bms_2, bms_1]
BO_ 265 bms_2: 8 Marvel
 SG_ Total_Pack_Voltage : 48|16@1+ (0.1,0) [0|6553.5] "V" Vector__XXX
 SG_ SOH : 16|16@1+ (0.01,0) [0|655.35] "%" Vector__XXX
 SG_ SOC : 0|16@1+ (0.01,0) [0|655.35] "%" Vector__XXX
 SG_ Flags_Fully_Charged : 40|8@1+ (1,0) [0|255] "" Vector__XXX
 SG_ BMS_Status : 32|8@1+ (1,0) [0|255] "" Vector__XXX

BO_ 264 bms_1: 8 Marvel
 SG_ Max_Allowed_Pack_Voltage : 16|16@1+ (1,0) [0|65535] "V" Vector__XXX
 SG_ Max_Allowed_Current : 48|16@1+ (1,0) [0|65535] "A" Vector__XXX
 SG_ Max_Allowed_Cell_Voltage : 0|16@1+ (1,0) [0|65535] "mV" Vector__XXX
 SG_ Max_Allowed_Cell_Temp : 32|16@1+ (1,0) [0|65535] "C" Vector__XXX

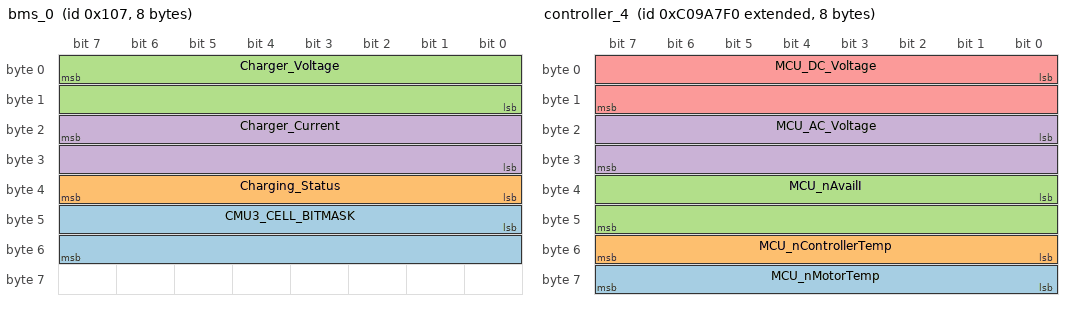
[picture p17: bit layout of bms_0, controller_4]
BO_ 263 bms_0: 8 Marvel
 SG_ CMU3_CELL_BITMASK : 40|16@1+ (1,0) [0|65535] "" Vector__XXX
 SG_ Charging_Status : 32|8@1+ (1,0) [0|255] "" Vector__XXX
 SG_ Charger_Voltage : 7|16@0+ (0.1,0) [0|65535] "mV" Vector__XXX
 SG_ Charger_Current : 23|16@0+ (0.1,0) [0|6553.5] "" Vector__XXX

BO_ 1798 controller_0: 8 Vector__XXX
 SG_ Regeneration_Active : 10|1@1+ (1,0) [0|0] "" Vector__XXX

BO_ 1830 controller_2: 8 Vector__XXX
 SG_ Firmware_Version : 32|32@1+ (1,0) [0|0] "" Vector__XXX
 SG_ Configuration_Version : 0|32@1+ (1,0) [0|0] "" Vector__XXX

BO_ 1829 controller_1: 2 Vector__XXX
 SG_ Inputs_Brake_Pot : 8|8@1+ (0.1,0) [0|0] "V" Vector__XXX
 SG_ Inputs_Brake_Command : 0|8@1+ (1,0) [0|0] "%" Vector__XXX

BO_ 2349508592 controller_5: 8 Vector__XXX
 SG_ MCU_N_FaultNUM : 56|3@1+ (1,0) [0|0] "" Vector__XXX
 SG_ MCU_N_FaultGrade : 52|4@1+ (1,0) [0|0] "" Vector__XXX
 SG_ MCU_F_RESERVE9 : 50|2@1+ (1,0) [0|0] "" Vector__XXX
 SG_ MCU_F_IGBT_HOC_WARNING : 49|1@1+ (1,0) [0|0] "" Vector__XXX
 SG_ MCU_F_ACC_UV_WARNING : 48|1@1+ (1,0) [0|0] "" Vector__XXX
 SG_ MCU_F_RESERVE8 : 47|1@1+ (1,0) [0|0] "" Vector__XXX
 SG_ MCU_F_MOTOR_TEMP_SENSOR : 46|1@1+ (1,0) [0|0] "" Vector__XXX
 SG_ MCU_F_IGBT_TEMP_SENSOR : 45|1@1+ (1,0) [0|0] "" Vector__XXX
 SG_ MCU_F_H_W_OC : 44|1@1+ (1,0) [0|0] "" Vector__XXX
 SG_ MCU_F_H_V_OC : 43|1@1+ (1,0) [0|0] "" Vector__XXX
 SG_ MCU_F_H_U_OC : 42|1@1+ (1,0) [0|0] "" Vector__XXX
 SG_ MCU_F_RESERVE7 : 41|1@1+ (1,0) [0|0] "" Vector__XXX
 SG_ MCU_F_W_DOWN_IGBT : 40|1@1+ (1,0) [0|0] "" Vector__XXX
 SG_ MCU_F_W_UP_IGBT : 39|1@1+ (1,0) [0|0] "" Vector__XXX
 SG_ MCU_F_V_DOWN_IGBT : 38|1@1+ (1,0) [0|0] "" Vector__XXX
 SG_ MCU_F_V_UP_IGBT : 37|1@1+ (1,0) [0|0] "" Vector__XXX
 SG_ MCU_F_U_DOWN_IGBT : 36|1@1+ (1,0) [0|0] "" Vector__XXX
 SG_ MCU_F_U_UP_IGBT : 35|1@1+ (1,0) [0|0] "" Vector__XXX
 SG_ MCU_F_RESERVE6 : 31|4@1+ (1,0) [0|0] "" Vector__XXX
 SG_ MCU_F_MOTOR_OT_H : 30|1@1+ (1,0) [0|0] "" Vector__XXX
 SG_ MCU_F_MOTOR_OT_L : 29|1@1+ (1,0) [0|0] "" Vector__XXX
 SG_ MCU_F_RESERVE5 : 25|4@1+ (1,0) [0|0] "" Vector__XXX
 SG_ MCU_F_IGBT_OT_H : 24|1@1+ (1,0) [0|0] "" Vector__XXX
 SG_ MCU_F_IGBT_OT_L : 23|1@1+ (1,0) [0|0] "" Vector__XXX
 SG_ MCU_F_CAN_OFFLINE : 22|1@1+ (1,0) [0|0] "" Vector__XXX
 SG_ MCU_F_SPEED_OV : 21|1@1+ (1,0) [0|0] "" Vector__XXX
 SG_ MCU_F_RESERVE4 : 19|2@1+ (1,0) [0|0] "" Vector__XXX
 SG_ MCU_F_CONTROL_OL_H : 18|1@1+ (1,0) [0|0] "" Vector__XXX
 SG_ MCU_F_CONTROL_OL_L : 17|1@1+ (1,0) [0|0] "" Vector__XXX
 SG_ MCU_F_BUS_OV_H : 16|1@1+ (1,0) [0|0] "" Vector__XXX
 SG_ MCU_F_BUS_OV_L : 15|1@1+ (1,0) [0|0] "" Vector__XXX
 SG_ MCU_F_BUS_UV_H : 14|1@1+ (1,0) [0|0] "" Vector__XXX
 SG_ MCU_F_BUS_UV_L : 13|1@1+ (1,0) [0|0] "" Vector__XXX
 SG_ MCU_F_S_OC : 12|1@1+ (1,0) [0|0] "" Vector__XXX
 SG_ MCU_F_ACC_UV : 11|1@1+ (1,0) [0|0] "" Vector__XXX
 SG_ MCU_F_GUN_SELF : 10|1@1+ (1,0) [0|0] "" Vector__XXX
 SG_ MCU_F_RESERVE3 : 8|2@1+ (1,0) [0|0] "" Vector__XXX
 SG_ MCU_F_CURRENT_DETECT : 7|1@1+ (1,0) [0|0] "" Vector__XXX
 SG_ MCU_F_LACK_PHASE : 6|1@1+ (1,0) [0|0] "" Vector__XXX
 SG_ MCU_F_ENCORDE : 5|1@1+ (1,0) [0|0] "" Vector__XXX
 SG_ MCU_F_RESERVE2 : 4|1@1+ (1,0) [0|0] "" Vector__XXX
 SG_ MCU_F_H_OV : 3|1@1+ (1,0) [0|0] "" Vector__XXX
 SG_ MCU_F_RESERVE1 : 2|1@1+ (1,0) [0|0] "" Vector__XXX
 SG_ MCU_F_H_OC : 1|1@1+ (1,0) [0|0] "" Vector__XXX
 SG_ MCU_F_IGBT : 0|1@1+ (1,0) [0|0] "" Vector__XXX

BO_ 2349443056 controller_4: 8 Vector__XXX
 SG_ MCU_nMotorTemp : 56|8@1+ (1,-40) [0|0] "��C" Vector__XXX
 SG_ MCU_nControllerTemp : 48|8@1+ (1,-40) [0|0] "��C" Vector__XXX
 SG_ MCU_nAvailI : 32|16@1+ (0.1,-3200) [0|0] "A" Vector__XXX
 SG_ MCU_AC_Voltage : 16|16@1+ (0.1,0) [0|0] "V" Vector__XXX
 SG_ MCU_DC_Voltage : 0|16@1+ (0.1,0) [0|0] "V" Vector__XXX

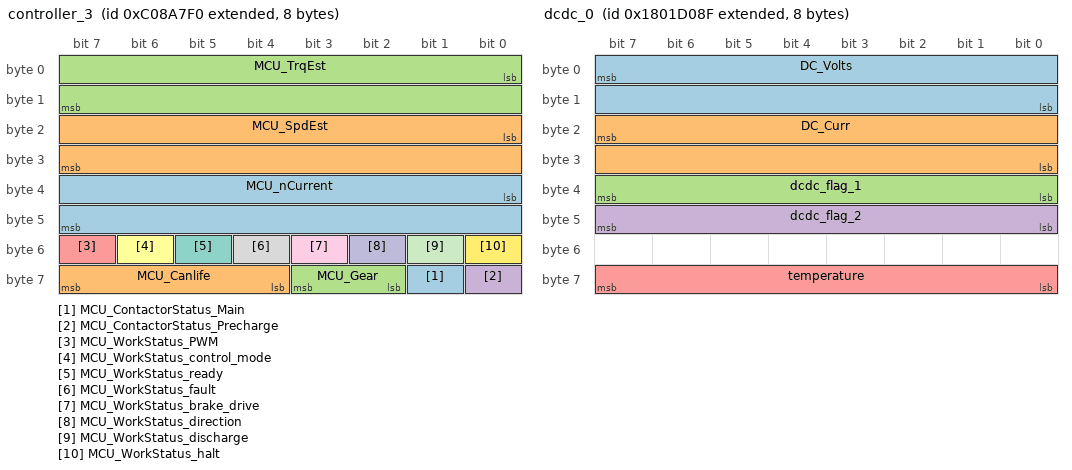
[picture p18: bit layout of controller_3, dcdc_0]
BO_ 2349377520 controller_3: 8 Vector__XXX
 SG_ MCU_ContactorStatus_Main : 57|1@1+ (1,0) [0|0] "" Vector__XXX
 SG_ MCU_Canlife : 60|4@1+ (1,0) [0|0] "" Vector__XXX
 SG_ MCU_Gear : 58|2@1+ (1,0) [0|0] "" Vector__XXX
 SG_ MCU_ContactorStatus_Precharge : 56|1@1+ (1,0) [0|0] "" Vector__XXX
 SG_ MCU_WorkStatus_PWM : 55|1@1+ (1,0) [0|0] "" Vector__XXX
 SG_ MCU_WorkStatus_control_mode : 54|1@1+ (1,0) [0|0] "" Vector__XXX
 SG_ MCU_WorkStatus_ready : 53|1@1+ (1,0) [0|0] "" Vector__XXX
 SG_ MCU_WorkStatus_fault : 52|1@1+ (1,0) [0|0] "" Vector__XXX
 SG_ MCU_WorkStatus_brake_drive : 51|1@1+ (1,0) [0|0] "" Vector__XXX
 SG_ MCU_WorkStatus_direction : 50|1@1+ (1,0) [0|0] "" Vector__XXX
 SG_ MCU_WorkStatus_discharge : 49|1@1+ (1,0) [0|0] "" Vector__XXX
 SG_ MCU_WorkStatus_halt : 48|1@1+ (1,0) [0|0] "" Vector__XXX
 SG_ MCU_nCurrent : 32|16@1+ (0.1,-3200) [0|0] "A" Vector__XXX
 SG_ MCU_SpdEst : 16|16@1+ (1,-32000) [0|0] "rpm" Vector__XXX
 SG_ MCU_TrqEst : 0|16@1+ (0.1,-3200) [0|0] "Nm" Vector__XXX

BO_ 2550255759 dcdc_0: 8 Vector__XXX
 SG_ DC_Volts : 7|16@0+ (0.1,0) [0|0] "" Vector__XXX
 SG_ DC_Curr : 23|16@0+ (0.1,0) [0|0] "" Vector__XXX
 SG_ dcdc_flag_1 : 39|8@0+ (1,0) [0|0] "" Vector__XXX
 SG_ dcdc_flag_2 : 47|8@0+ (1,0) [0|0] "" Vector__XXX
 SG_ temperature : 63|8@0+ (1,-40) [0|0] "" Vector__XXX

CM_ BO_ 3221225472 "This is a message for not used signals, created by Vector CANdb++ DBC OLE DB Provider.";
CM_ SG_ 3221225472 VCU_Canlife "VCU�����ź�";
CM_ SG_ 3221225472 VCU_HVCircuit "ĸ��״̬";
CM_ SG_ 3221225472 VCU_Discharge "�����ŵ�����";
CM_ SG_ 3221225472 VCU_Enable "ʹ���ź�";
CM_ SG_ 3221225472 VCU_ModeReq_control_mode "����ģʽ����_����ģʽ";
CM_ SG_ 3221225472 VCU_ModeReq_reverse "����ģʽ����_����";
CM_ SG_ 3221225472 VCU_ModeReq_brake "����ģʽ����_ɲ��";
CM_ SG_ 3221225472 VCU_ModeReq_forward "����ģʽ����_ǰ��";
CM_ SG_ 3221225472 VCU_ModeReq_idle "����ģʽ����_����";
CM_ SG_ 3221225472 VCU_ModeReq_halt "����ģʽ����_����";
CM_ SG_ 3221225472 VCU_SpdReq "ת������";
CM_ SG_ 3221225472 VCU_TrqReq "Ť������";
CM_ SG_ 1798 Regeneration_Active "���ռ����־";
CM_ SG_ 1830 Firmware_Version "�̼��汾";
CM_ SG_ 1830 Configuration_Version "���ð汾";
CM_ SG_ 1829 Inputs_Brake_Pot "ɲ����ѹ";
CM_ SG_ 1829 Inputs_Brake_Command "ɲ���ٷֱ�";
CM_ SG_ 2349508592 MCU_N_FaultNUM "���ϸ���";
CM_ SG_ 2349508592 MCU_N_FaultGrade "���ϵȼ�";
CM_ SG_ 2349508592 MCU_F_RESERVE9 "Ԥ��9";
CM_ SG_ 2349508592 MCU_F_IGBT_HOC_WARNING "����Ԥ��";
CM_ SG_ 2349508592 MCU_F_ACC_UV_WARNING "��ѹǷѹԤ��";
CM_ SG_ 2349508592 MCU_F_RESERVE8 "Ԥ��8";
CM_ SG_ 2349508592 MCU_F_MOTOR_TEMP_SENSOR "����¶ȴ���������";
CM_ SG_ 2349508592 MCU_F_IGBT_TEMP_SENSOR "IGBT�¶ȴ���������";
CM_ SG_ 2349508592 MCU_F_H_W_OC "W��Ӳ����������";
CM_ SG_ 2349508592 MCU_F_H_V_OC "V��Ӳ����������";
CM_ SG_ 2349508592 MCU_F_H_U_OC "U��Ӳ����������";
CM_ SG_ 2349508592 MCU_F_RESERVE7 "Ԥ��7";
CM_ SG_ 2349508592 MCU_F_W_DOWN_IGBT "W������IGBT����";
CM_ SG_ 2349508592 MCU_F_W_UP_IGBT "W������IGBT����";
CM_ SG_ 2349508592 MCU_F_V_DOWN_IGBT "V������IGBT����";
CM_ SG_ 2349508592 MCU_F_V_UP_IGBT "V������IGBT����";
CM_ SG_ 2349508592 MCU_F_U_DOWN_IGBT "U������IGBT����";
CM_ SG_ 2349508592 MCU_F_U_UP_IGBT "U������IGBT����";
CM_ SG_ 2349508592 MCU_F_RESERVE6 "Ԥ��6";
CM_ SG_ 2349508592 MCU_F_MOTOR_OT_H "������ع��¹���";
CM_ SG_ 2349508592 MCU_F_MOTOR_OT_L "���һ����¹���";
CM_ SG_ 2349508592 MCU_F_RESERVE5 "Ԥ��5";
CM_ SG_ 2349508592 MCU_F_IGBT_OT_H "IGBT���ع��¹���";
CM_ SG_ 2349508592 MCU_F_IGBT_OT_L "IGBTһ����¹���";
CM_ SG_ 2349508592 MCU_F_CAN_OFFLINE "���߳�ʱ����";
CM_ SG_ 2349508592 MCU_F_SPEED_OV "���ٹ���";
CM_ SG_ 2349508592 MCU_F_RESERVE4 "Ԥ��4";
CM_ SG_ 2349508592 MCU_F_CONTROL_OL_H "���������ع���";
CM_ SG_ 2349508592 MCU_F_CONTROL_OL_L "����������Ԥ������";
CM_ SG_ 2349508592 MCU_F_BUS_OV_H "���ع�ѹ����";
CM_ SG_ 2349508592 MCU_F_BUS_OV_L "һ���ѹ����";
CM_ SG_ 2349508592 MCU_F_BUS_UV_H "����Ƿѹ���� ";
CM_ SG_ 2349508592 MCU_F_BUS_UV_L "һ��Ƿѹ����";
CM_ SG_ 2349508592 MCU_F_S_OC "������������";
CM_ SG_ 2349508592 MCU_F_ACC_UV "��ѹ����Ƿѹ����";
CM_ SG_ 2349508592 MCU_F_GUN_SELF "�����Լ����";
CM_ SG_ 2349508592 MCU_F_RESERVE3 "Ԥ��3";
CM_ SG_ 2349508592 MCU_F_CURRENT_DETECT "����������";
CM_ SG_ 2349508592 MCU_F_LACK_PHASE "���ȱ�����";
CM_ SG_ 2349508592 MCU_F_ENCORDE "����������";
CM_ SG_ 2349508592 MCU_F_RESERVE2 "Ԥ��2";
CM_ SG_ 2349508592 MCU_F_H_OV "ĸ��Ӳ����ѹ����";
CM_ SG_ 2349508592 MCU_F_RESERVE1 "Ԥ��1";
CM_ SG_ 2349508592 MCU_F_H_OC "Ӳ����������";
CM_ SG_ 2349508592 MCU_F_IGBT "IGBT����";
CM_ SG_ 2349443056 MCU_nMotorTemp "����¶�";
CM_ SG_ 2349443056 MCU_nControllerTemp "����������¶�";
CM_ SG_ 2349443056 MCU_nAvailI "������Чֵ";
CM_ SG_ 2349443056 MCU_AC_Voltage "MCU������ѹ";
CM_ SG_ 2349443056 MCU_DC_Voltage "MCUֱ����ѹ";
CM_ SG_ 2349377520 MCU_ContactorStatus_Main "���Ӵ���״̬";
CM_ SG_ 2349377520 MCU_Canlife "MCU�����ź�";
CM_ SG_ 2349377520 MCU_Gear "MCU��ǰ��λ";
CM_ SG_ 2349377520 MCU_ContactorStatus_Precharge "Ԥ��Ӵ���״̬";
CM_ SG_ 2349377520 MCU_WorkStatus_PWM " MCU����״̬_PWM";
CM_ SG_ 2349377520 MCU_WorkStatus_control_mode "MCU����״̬_����ģʽ";
CM_ SG_ 2349377520 MCU_WorkStatus_ready "MCU����״̬_׼��";
CM_ SG_ 2349377520 MCU_WorkStatus_fault "MCU����״̬_����";
CM_ SG_ 2349377520 MCU_WorkStatus_brake_drive "MCU����״̬_ɲ������";
CM_ SG_ 2349377520 MCU_WorkStatus_direction "MCU����״̬_�������";
CM_ SG_ 2349377520 MCU_WorkStatus_discharge "MCU����״̬_�����ŵ�";
CM_ SG_ 2349377520 MCU_WorkStatus_halt "MCU����״̬_����";
CM_ SG_ 2349377520 MCU_nCurrent "ֱ��ĸ�ߵ���";
CM_ SG_ 2349377520 MCU_SpdEst "���ʵ��ת��";
CM_ SG_ 2349377520 MCU_TrqEst "������Ť��";
BA_DEF_ SG_  "SystemSignalLongSymbol" STRING ;
BA_DEF_DEF_  "SystemSignalLongSymbol" "";
BA_ "SystemSignalLongSymbol" SG_ 3221225472 battery_remaining_battery_capaci "battery_remaining_battery_capacity";
BA_ "SystemSignalLongSymbol" SG_ 3221225472 controller_battery_energy_consum "controller_battery_energy_consumed";
BA_ "SystemSignalLongSymbol" SG_ 3221225472 controller_battery_power_consume "controller_battery_power_consumed";
BA_ "SystemSignalLongSymbol" SG_ 3221225472 controller_motor_torque_estimate "controller_motor_torque_estimated";
BA_ "SystemSignalLongSymbol" SG_ 3221225472 controller_battery_keyswitch_vol "controller_battery_keyswitch_voltage";
BA_ "SystemSignalLongSymbol" SG_ 3221225472 controller_battery_capacity_volt "controller_battery_capacity_voltage";
BA_ "SystemSignalLongSymbol" SG_ 3221225472 controller_throttle_potentiomete "controller_throttle_potentiometer";
BA_ "SystemSignalLongSymbol" SG_ 3221225472 controller_battery_discharge_rat "controller_battery_discharge_rate";
VAL_ 2349508592 MCU_F_IGBT_HOC_WARNING 1 "fault" 0 "normal" ;
VAL_ 2349508592 MCU_F_ACC_UV_WARNING 1 "fault" 0 "normal" ;
VAL_ 2349508592 MCU_F_MOTOR_TEMP_SENSOR 1 "fault" 0 "normal" ;
VAL_ 2349508592 MCU_F_IGBT_TEMP_SENSOR 1 "fault" 0 "normal" ;
VAL_ 2349508592 MCU_F_H_W_OC 1 "fault" 0 "normal" ;
VAL_ 2349508592 MCU_F_H_V_OC 1 "fault" 0 "normal" ;
VAL_ 2349508592 MCU_F_H_U_OC 1 "fault" 0 "normal" ;
VAL_ 2349508592 MCU_F_W_DOWN_IGBT 1 "fault" 0 "normal" ;
VAL_ 2349508592 MCU_F_W_UP_IGBT 1 "fault" 0 "normal" ;
VAL_ 2349508592 MCU_F_V_DOWN_IGBT 1 "fault" 0 "normal" ;
VAL_ 2349508592 MCU_F_V_UP_IGBT 1 "fault" 0 "normal" ;
VAL_ 2349508592 MCU_F_U_DOWN_IGBT 1 "fault" 0 "normal" ;
VAL_ 2349508592 MCU_F_U_UP_IGBT 1 "fault" 0 "normal" ;
VAL_ 2349508592 MCU_F_MOTOR_OT_H 1 "fault" 0 "normal" ;
VAL_ 2349508592 MCU_F_MOTOR_OT_L 1 "fault" 0 "normal" ;
VAL_ 2349508592 MCU_F_IGBT_OT_H 1 "fault" 0 "normal" ;
VAL_ 2349508592 MCU_F_IGBT_OT_L 1 "fault" 0 "normal" ;
VAL_ 2349508592 MCU_F_CAN_OFFLINE 1 "fault" 0 "normal" ;
VAL_ 2349508592 MCU_F_SPEED_OV 1 "fault" 0 "normal" ;
VAL_ 2349508592 MCU_F_CONTROL_OL_H 1 "fault" 0 "normal" ;
VAL_ 2349508592 MCU_F_CONTROL_OL_L 1 "fault" 0 "normal" ;
VAL_ 2349508592 MCU_F_BUS_OV_H 1 "fault" 0 "normal" ;
VAL_ 2349508592 MCU_F_BUS_OV_L 1 "fault" 0 "normal" ;
VAL_ 2349508592 MCU_F_BUS_UV_H 1 "fault" 0 "normal" ;
VAL_ 2349508592 MCU_F_BUS_UV_L 1 "fault" 0 "normal" ;
VAL_ 2349508592 MCU_F_S_OC 1 "fault" 0 "normal" ;
VAL_ 2349508592 MCU_F_ACC_UV 1 "fault" 0 "normal" ;
VAL_ 2349508592 MCU_F_GUN_SELF 1 "fault" 0 "normal" ;
VAL_ 2349508592 MCU_F_CURRENT_DETECT 1 "fault" 0 "normal" ;
VAL_ 2349508592 MCU_F_LACK_PHASE 1 "fault" 0 "normal" ;
VAL_ 2349508592 MCU_F_ENCORDE 1 "fault" 0 "normal" ;
VAL_ 2349508592 MCU_F_H_OV 1 "fault" 0 "normal" ;
VAL_ 2349508592 MCU_F_H_OC 1 "fault" 0 "normal" ;
VAL_ 2349508592 MCU_F_IGBT 1 "fault" 0 "normal" ;
VAL_ 2349377520 MCU_ContactorStatus_Main 1 "main contactor on" 0 "main contactor off" ;
VAL_ 2349377520 MCU_Gear 3 "Brake" 2 "R" 1 "D" 0 "N" ;
VAL_ 2349377520 MCU_ContactorStatus_Precharge 1 "precharge on" 0 "precharge off" ;
VAL_ 2349377520 MCU_WorkStatus_PWM 1 "PWM on" 0 "PWM off" ;
VAL_ 2349377520 MCU_WorkStatus_control_mode 1 "Speed mode" 0 "Torque mode" ;
VAL_ 2349377520 MCU_WorkStatus_ready 1 "Ready" 0 "Not Ready" ;
VAL_ 2349377520 MCU_WorkStatus_fault 1 "fault" 0 "no fault" ;
VAL_ 2349377520 MCU_WorkStatus_brake_drive 1 "Description for the value '0x1'" 0 "brake" ;
VAL_ 2349377520 MCU_WorkStatus_direction 1 "motor forward" 0 "motor reverse" ;
VAL_ 2349377520 MCU_WorkStatus_discharge 1 "active discharge on" 0 "active discharge off" ;
VAL_ 2349377520 MCU_WorkStatus_halt 1 "start" 0 "halt" ;
